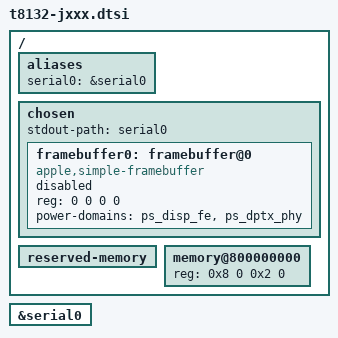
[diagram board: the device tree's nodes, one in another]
// SPDX-License-Identifier: GPL-2.0+ OR MIT
/*
 * Apple M4 Mac mini, MacBook Air/Pro, iMac 24" (M4, 2024/2025)
 *
 * This file contains parts common to all Apple M4 devices using the t8132.
 *
 * target-type: J604, J623, J624, J713, J715, J773g
 *
 * Copyright The Asahi Linux Contributors
 */

/ {
	aliases {
		serial0 = &serial0;
	};

	chosen {
		#address-cells = <2>;
		#size-cells = <2>;
		ranges;

		stdout-path = "serial0";

		framebuffer0: framebuffer@0 {
			compatible = "apple,simple-framebuffer", "simple-framebuffer";
			reg = <0 0 0 0>; /* To be filled by loader */
			power-domains = <&ps_disp_fe>, <&ps_dptx_phy>;
			/* Format properties will be added by loader */
			status = "disabled";
		};
	};

	reserved-memory {
		#address-cells = <2>;
		#size-cells = <2>;
		ranges;
		/* To be filled by loader */
	};

	memory@800000000 {
		device_type = "memory";
		reg = <0x8 0 0x2 0>; /* To be filled by loader */
	};
};

&serial0 {
	status = "okay";
};
